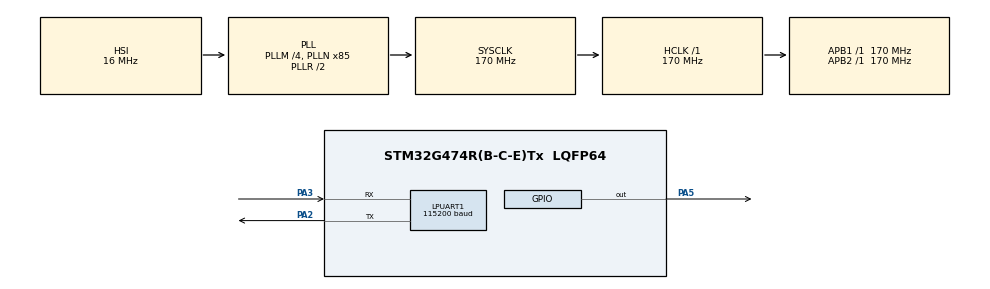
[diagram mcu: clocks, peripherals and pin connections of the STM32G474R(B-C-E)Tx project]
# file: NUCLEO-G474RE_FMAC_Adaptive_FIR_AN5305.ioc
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Dma.FMAC_PRELOAD.0.Direction=DMA_MEMORY_TO_MEMORY
Dma.FMAC_PRELOAD.0.EventEnable=DISABLE
Dma.FMAC_PRELOAD.0.Instance=DMA1_Channel1
Dma.FMAC_PRELOAD.0.MemDataAlignment=DMA_MDATAALIGN_WORD
Dma.FMAC_PRELOAD.0.MemInc=DMA_MINC_DISABLE
Dma.FMAC_PRELOAD.0.Mode=DMA_NORMAL
Dma.FMAC_PRELOAD.0.PeriphDataAlignment=DMA_PDATAALIGN_HALFWORD
Dma.FMAC_PRELOAD.0.PeriphInc=DMA_PINC_ENABLE
Dma.FMAC_PRELOAD.0.Polarity=HAL_DMAMUX_REQ_GEN_RISING
Dma.FMAC_PRELOAD.0.Priority=DMA_PRIORITY_HIGH
Dma.FMAC_PRELOAD.0.RequestNumber=1
Dma.FMAC_PRELOAD.0.SignalID=NONE
Dma.FMAC_PRELOAD.0.SyncEnable=DISABLE
Dma.FMAC_PRELOAD.0.SyncPolarity=HAL_DMAMUX_SYNC_NO_EVENT
Dma.FMAC_PRELOAD.0.SyncRequestNumber=1
Dma.FMAC_PRELOAD.0.SyncSignalID=NONE
Dma.FMAC_READ.2.Direction=DMA_PERIPH_TO_MEMORY
Dma.FMAC_READ.2.EventEnable=DISABLE
Dma.FMAC_READ.2.Instance=DMA1_Channel3
Dma.FMAC_READ.2.MemDataAlignment=DMA_MDATAALIGN_HALFWORD
Dma.FMAC_READ.2.MemInc=DMA_MINC_ENABLE
Dma.FMAC_READ.2.Mode=DMA_NORMAL
Dma.FMAC_READ.2.PeriphDataAlignment=DMA_PDATAALIGN_WORD
Dma.FMAC_READ.2.PeriphInc=DMA_PINC_DISABLE
Dma.FMAC_READ.2.Polarity=HAL_DMAMUX_REQ_GEN_RISING
Dma.FMAC_READ.2.Priority=DMA_PRIORITY_HIGH
Dma.FMAC_READ.2.RequestNumber=1
Dma.FMAC_READ.2.SignalID=NONE
Dma.FMAC_READ.2.SyncEnable=DISABLE
Dma.FMAC_READ.2.SyncPolarity=HAL_DMAMUX_SYNC_NO_EVENT
Dma.FMAC_READ.2.SyncRequestNumber=1
Dma.FMAC_READ.2.SyncSignalID=NONE
Dma.FMAC_WRITE.1.Direction=DMA_MEMORY_TO_PERIPH
Dma.FMAC_WRITE.1.EventEnable=DISABLE
Dma.FMAC_WRITE.1.Instance=DMA1_Channel2
Dma.FMAC_WRITE.1.MemDataAlignment=DMA_MDATAALIGN_HALFWORD
Dma.FMAC_WRITE.1.MemInc=DMA_MINC_ENABLE
Dma.FMAC_WRITE.1.Mode=DMA_NORMAL
Dma.FMAC_WRITE.1.PeriphDataAlignment=DMA_PDATAALIGN_WORD
Dma.FMAC_WRITE.1.PeriphInc=DMA_PINC_DISABLE
Dma.FMAC_WRITE.1.Polarity=HAL_DMAMUX_REQ_GEN_RISING
Dma.FMAC_WRITE.1.Priority=DMA_PRIORITY_HIGH
Dma.FMAC_WRITE.1.RequestNumber=1
Dma.FMAC_WRITE.1.SignalID=NONE
Dma.FMAC_WRITE.1.SyncEnable=DISABLE
Dma.FMAC_WRITE.1.SyncPolarity=HAL_DMAMUX_SYNC_NO_EVENT
Dma.FMAC_WRITE.1.SyncRequestNumber=1
Dma.FMAC_WRITE.1.SyncSignalID=NONE
Dma.Request0=FMAC_PRELOAD
Dma.Request1=FMAC_WRITE
Dma.Request2=FMAC_READ
LPUART1.BaudRate=115200
Mcu.Family=STM32G4
Mcu.Name=STM32G474R(B-C-E)Tx
Mcu.Package=LQFP64
NVIC.DMA1_Channel1_IRQn=true\:0\:0\:false\:false\:true\:false\:true
NVIC.DMA1_Channel2_IRQn=true\:0\:0\:false\:false\:true\:false\:true
NVIC.DMA1_Channel3_IRQn=true\:0\:0\:false\:false\:true\:false\:true
NVIC.FMAC_IRQn=true\:1\:0\:true\:false\:true\:true\:true
NVIC.PriorityGroup=NVIC_PRIORITYGROUP_4
PA2.Mode=Asynchronous
PA2.Signal=LPUART1_TX
PA3.Mode=Asynchronous
PA3.Signal=LPUART1_RX
PA5.Signal=GPIO_Output
ProjectManager.HeapSize=0x200
ProjectManager.StackSize=0x400
ProjectManager.TargetToolchain=STM32CubeIDE
RCC.ADC12Freq_Value=170000000
RCC.ADC345Freq_Value=170000000
RCC.AHBFreq_Value=170000000
RCC.APB1Freq_Value=170000000
RCC.APB1TimFreq_Value=170000000
RCC.APB2Freq_Value=170000000
RCC.APB2TimFreq_Value=170000000
RCC.CortexFreq_Value=170000000
RCC.EXTERNAL_CLOCK_VALUE=12288000
RCC.HCLKFreq_Value=170000000
RCC.HSE_VALUE=24000000
RCC.HSI48_VALUE=48000000
RCC.HSI_VALUE=16000000
RCC.LSE_VALUE=32768
RCC.PLLM=RCC_PLLM_DIV4
RCC.PLLN=85
RCC.SYSCLKFreq_VALUE=170000000
RCC.SYSCLKSource=RCC_SYSCLKSOURCE_PLLCLK
RCC.USBFreq_Value=170000000
RCC.VCOOutputFreq_Value=340000000
VP_FMAC_VS_FMAC.Mode=FMAC_Activate
VP_SYS_VS_DBSignals.Mode=DisableDeadBatterySignals
board=NUCLEO-G474RE

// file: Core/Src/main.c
/* USER CODE BEGIN Header */
/**
  ******************************************************************************
  * @file    FMAC/FMAC_Adaptive_FIR_AN5305/Src/main.c
  * @author  MCD Application Team
  * @brief   This sample code shows how to use FMAC HAL API (FMAC instance)
  *          to perform an adaptive FIR filter in DMA mode.
  ******************************************************************************
  * @attention
  *
  * <h2><center>&copy; Copyright (c) 2019 STMicroelectronics.
  * All rights reserved.</center></h2>
  *
  * This software component is licensed by ST under BSD 3-Clause license,
  * the "License"; You may not use this file except in compliance with the
  * License. You may obtain a copy of the License at:
  *                        opensource.org/licenses/BSD-3-Clause
  *
  ******************************************************************************
  */
/* USER CODE END Header */
#include "main.h"

/* USER CODE BEGIN Includes */
#include <stdio.h>
#include "2ToneNoise.h"
#include "3ToneNoise.h"
//#include "stm32g4xx_nucleo.h"
/* USER CODE END Includes */

FMAC_HandleTypeDef hfmac;
DMA_HandleTypeDef hdma_fmac_preload;
DMA_HandleTypeDef hdma_fmac_write;
DMA_HandleTypeDef hdma_fmac_read;

UART_HandleTypeDef hlpuart1;

/* USER CODE BEGIN PV */
/* FMAC configuration structure */
FMAC_FilterConfigTypeDef sFmacConfig;

/* Array of input values in Q1.15 format */
static int16_t aInputValues[2][ARRAY_SIZE];

static int16_t aFilterCoeffB[COEFF_VECTOR_B_SIZE];

/* Array of calculated filtered data in Q1.15 format (two parts) */
static int16_t aCalculatedFilteredData[ARRAY_SIZE];

/* Expected number of calculated samples for the used aCalculatedFilteredDataX */
uint16_t CurrentInputArraySize;

/* Expected number of calculated samples for the used aCalculatedFilteredDataX */
uint16_t ExpectedCalculatedFilteredDataSize;

/* Status of the calculation */
__IO uint32_t FilterPreloadCallbackCount   = 0;
__IO uint32_t HalfGetDataCallbackCount     = 0;
__IO uint32_t GetDataCallbackCount         = 0;
__IO uint32_t OutputDataReadyCallbackCount = 0;
__IO uint32_t ErrorCount                   = 0;
uint32_t OldValue;

/* Frame selelector */
uint8_t OldFrame = 0;
uint8_t Frame = 1;
/* Auxiliary counter */
uint32_t Index;

float value_f32;

/* USER CODE END PV */

void SystemClock_Config(void);
static void MX_GPIO_Init(void);
static void MX_DMA_Init(void);
static void MX_FMAC_Init(void);
static void MX_LPUART1_UART_Init(void);
/* USER CODE BEGIN PFP */

#define PUTCHAR_PROTOTYPE int __io_putchar(int ch)

/* USER CODE END PFP */

int main(void)
{
  /* USER CODE BEGIN 1 */
  /* STM32G4xx HAL library initialization:
       - Configure the Flash prefetch
       - Systick timer is configured by default as source of time base, but user
         can eventually implement his proper time base source (a general purpose
         timer for example or other time source), keeping in mind that Time base
         duration should be kept 1ms since PPP_TIMEOUT_VALUEs are defined and
         handled in milliseconds basis.
       - Set NVIC Group Priority to 4
       - Low Level Initialization
     */
  /* USER CODE END 1 */

  /* MCU Configuration--------------------------------------------------------*/

  /* Reset of all peripherals, Initializes the Flash interface and the Systick. */
  HAL_Init();

  /* Configure the system clock */
  SystemClock_Config();

  /* USER CODE BEGIN SysInit */
  /* Configure LED2 */

  /* USER CODE END SysInit */

  /* Initialize all configured peripherals */
  MX_GPIO_Init();
  MX_DMA_Init();
  MX_FMAC_Init();
  MX_LPUART1_UART_Init();
  /* USER CODE BEGIN 2 */
  /* Fill first frame with input signal and zero the other frame */
  /* Normally samples would come from ADC or other source, in this example the */
  /* same data is reloaded from Flash */

  printf("TwoToneNoise\n");
  for (Index=0; Index<ARRAY_SIZE; Index++)
  {
    aInputValues[0][Index] = TwoToneNoise[Index];
    aInputValues[1][Index] = 0;
    printf("%d %d\n",Index, TwoToneNoise[Index]);
  }

  /* generate filter coefficents (in this example they are simply read from flash */
  printf("TwoToneFilter\n");
  for (Index=0; Index<COEFF_VECTOR_B_SIZE; Index++)
  {
    aFilterCoeffB[Index] = TwoToneFilter[Index];
    printf("%d %d\n",Index, TwoToneFilter[Index]);
  }

  /*## Static FMAC configuration parameters #################################*/
  sFmacConfig.InputBaseAddress  = INPUT_BUFFER_BASE;
  sFmacConfig.InputBufferSize   = INPUT_BUFFER_SIZE;
  sFmacConfig.InputThreshold    = INPUT_THRESHOLD;
  sFmacConfig.CoeffBaseAddress  = COEFFICIENT_BUFFER_BASE;
  sFmacConfig.CoeffBufferSize   = COEFFICIENT_BUFFER_SIZE;
  sFmacConfig.OutputBaseAddress = OUTPUT_BUFFER_BASE;
  sFmacConfig.OutputBufferSize  = OUTPUT_BUFFER_SIZE;
  sFmacConfig.OutputThreshold   = OUTPUT_THRESHOLD;
  sFmacConfig.pCoeffA           = NULL;
  sFmacConfig.CoeffASize        = 0;
  sFmacConfig.CoeffBSize        = COEFF_VECTOR_B_SIZE;
  sFmacConfig.Filter            = FMAC_FUNC_CONVO_FIR;
  sFmacConfig.InputAccess       = FMAC_BUFFER_ACCESS_DMA;
  sFmacConfig.OutputAccess      = FMAC_BUFFER_ACCESS_DMA;
#if defined(CLIP_ENABLED)
  sFmacConfig.Clip              = FMAC_CLIP_ENABLED;
#else
  sFmacConfig.Clip              = FMAC_CLIP_DISABLED;
#endif
  sFmacConfig.P                 = COEFF_VECTOR_B_SIZE;
  sFmacConfig.Q                 = FILTER_PARAM_Q_NOT_USED;
  sFmacConfig.R                 = GAIN;

  /*### Main loop repeats each frame ########################################*/
  /* Repeat until required number of frames have been processed */
  do {
    /* Point to filter coefficients for current frame*/
    sFmacConfig.pCoeffB           = aFilterCoeffB;
    /* Configure filter and load coefficients by polling */
    if (HAL_FMAC_FilterConfig(&hfmac, &sFmacConfig) != HAL_OK)
    {
      /* Configuration Error */
      Error_Handler();
    }

    /* Preload the filter state at end of previous frame */
    if (HAL_FMAC_FilterPreload_DMA(&hfmac, &aInputValues[Frame][ARRAY_SIZE-COEFF_VECTOR_B_SIZE+1], COEFF_VECTOR_B_SIZE-1, NULL, 0) != HAL_OK)
    {
      /* Configuration Error */
      Error_Handler();
    }
    /* Switch input frames */
    OldFrame = Frame;
    Frame = (Frame ? 0 : 1);

    /* Wait for preload to finish */
    while (HAL_FMAC_GetState(&hfmac) != HAL_FMAC_STATE_READY);

    /* Start calculation of FIR filter in DMA mode */
    ExpectedCalculatedFilteredDataSize = ARRAY_SIZE;
    if (HAL_FMAC_FilterStart(&hfmac, aCalculatedFilteredData, &ExpectedCalculatedFilteredDataSize) != HAL_OK)
    {
      /* Processing Error */
      Error_Handler();
    }

    /*## Append data to start the DMA process after the preloaded data handling ##*/
    CurrentInputArraySize = ARRAY_SIZE;
    if (HAL_FMAC_AppendFilterData(&hfmac,
                                &aInputValues[Frame][0],
                                &CurrentInputArraySize) != HAL_OK)
    {
      ErrorCount++;
    }
    /* While processing is going on, fill next frame with input signal */
    /* Normally samples would come from ADC or other source, in this example the */
    /* data are loaded from Flash */
    printf("ThreeToneNoise\n");
    for (Index=0; Index<ARRAY_SIZE; Index++)
    {
      aInputValues[OldFrame][Index] = ThreeToneNoise[Index];
      printf("%d %d\n",Index, ThreeToneNoise[Index]);
    }
    /* Update filter coefficients for next frame */
    /* Normally this would be done by the adaptive algorithm, in this example the */
    /* coefficients are loaded from flash */
    printf("ThreeToneFilter\n");
    for (Index=0; Index<COEFF_VECTOR_B_SIZE; Index++)
    {
      aFilterCoeffB[Index] = ThreeToneFilter[Index];
      printf("%d %d\n",Index, ThreeToneFilter[Index]);
    }
    /* Wait for FMAC to finish processing frame */
    while (OutputDataReadyCallbackCount == OldValue);
    OldValue = OutputDataReadyCallbackCount;

    /* Stop the calculation of FIR filter in polling/DMA mode */
    if (HAL_FMAC_FilterStop(&hfmac) != HAL_OK)
    {
      /* Processing Error */
      Error_Handler();
    }
  /* end of loop */
  } while(OutputDataReadyCallbackCount < DATA_RDY_CALLBACK_COUNT);
  {
    if(ErrorCount != 0)
    {
      /* Processing Error */
      Error_Handler();
    }
  }

  /*## Check the final error status ############################################*/
  if(ErrorCount != 0)
  {
    /* Processing Error */
    Error_Handler();
  }

  /* Reached the end of processing : Turn LED2 on */
  HAL_GPIO_WritePin(GPIOA, GPIO_PIN_5, SET);

//#ifdef PRINT_OUTPUT
//  printf("Filtered output for frame %d\n",Frame);
//  for (Index=0; Index<ARRAY_SIZE; Index++)
//    printf("%d\n",aCalculatedFilteredData[Index]);
//#endif

  #ifdef PRINT_OUTPUT
    printf("Filtered output for frame %d\n",Frame);
    for (Index=0; Index<ARRAY_SIZE; Index++)
      printf("%d %d\n",Index, aCalculatedFilteredData[Index]);
  #endif

  /* USER CODE END 2 */

  /* Infinite loop */
  while (1)
  {

  }
}

void SystemClock_Config(void)
{
  RCC_OscInitTypeDef RCC_OscInitStruct = {0};
  RCC_ClkInitTypeDef RCC_ClkInitStruct = {0};
  RCC_PeriphCLKInitTypeDef PeriphClkInit = {0};

  /** Configure the main internal regulator output voltage
  */
  HAL_PWREx_ControlVoltageScaling(PWR_REGULATOR_VOLTAGE_SCALE1_BOOST);
  /** Initializes the RCC Oscillators according to the specified parameters
  * in the RCC_OscInitTypeDef structure.
  */
  RCC_OscInitStruct.OscillatorType = RCC_OSCILLATORTYPE_HSI;
  RCC_OscInitStruct.HSIState = RCC_HSI_ON;
  RCC_OscInitStruct.HSICalibrationValue = RCC_HSICALIBRATION_DEFAULT;
  RCC_OscInitStruct.PLL.PLLState = RCC_PLL_ON;
  RCC_OscInitStruct.PLL.PLLSource = RCC_PLLSOURCE_HSI;
  RCC_OscInitStruct.PLL.PLLM = RCC_PLLM_DIV4;
  RCC_OscInitStruct.PLL.PLLN = 85;
  RCC_OscInitStruct.PLL.PLLP = RCC_PLLP_DIV2;
  RCC_OscInitStruct.PLL.PLLQ = RCC_PLLQ_DIV2;
  RCC_OscInitStruct.PLL.PLLR = RCC_PLLR_DIV2;
  if (HAL_RCC_OscConfig(&RCC_OscInitStruct) != HAL_OK)
  {
    Error_Handler();
  }
  /** Initializes the CPU, AHB and APB buses clocks
  */
  RCC_ClkInitStruct.ClockType = RCC_CLOCKTYPE_HCLK|RCC_CLOCKTYPE_SYSCLK
                              |RCC_CLOCKTYPE_PCLK1|RCC_CLOCKTYPE_PCLK2;
  RCC_ClkInitStruct.SYSCLKSource = RCC_SYSCLKSOURCE_PLLCLK;
  RCC_ClkInitStruct.AHBCLKDivider = RCC_SYSCLK_DIV1;
  RCC_ClkInitStruct.APB1CLKDivider = RCC_HCLK_DIV1;
  RCC_ClkInitStruct.APB2CLKDivider = RCC_HCLK_DIV1;

  if (HAL_RCC_ClockConfig(&RCC_ClkInitStruct, FLASH_LATENCY_4) != HAL_OK)
  {
    Error_Handler();
  }
  /** Initializes the peripherals clocks
  */
  PeriphClkInit.PeriphClockSelection = RCC_PERIPHCLK_LPUART1;
  PeriphClkInit.Lpuart1ClockSelection = RCC_LPUART1CLKSOURCE_PCLK1;
  if (HAL_RCCEx_PeriphCLKConfig(&PeriphClkInit) != HAL_OK)
  {
    Error_Handler();
  }
}

static void MX_FMAC_Init(void)
{

  hfmac.Instance = FMAC;
  if (HAL_FMAC_Init(&hfmac) != HAL_OK)
  {
    Error_Handler();
  }

}

static void MX_LPUART1_UART_Init(void)
{

  hlpuart1.Instance = LPUART1;
  hlpuart1.Init.BaudRate = 115200;
  hlpuart1.Init.WordLength = UART_WORDLENGTH_8B;
  hlpuart1.Init.StopBits = UART_STOPBITS_1;
  hlpuart1.Init.Parity = UART_PARITY_NONE;
  hlpuart1.Init.Mode = UART_MODE_TX_RX;
  hlpuart1.Init.HwFlowCtl = UART_HWCONTROL_NONE;
  hlpuart1.Init.OneBitSampling = UART_ONE_BIT_SAMPLE_DISABLE;
  hlpuart1.Init.ClockPrescaler = UART_PRESCALER_DIV1;
  hlpuart1.AdvancedInit.AdvFeatureInit = UART_ADVFEATURE_NO_INIT;
  if (HAL_UART_Init(&hlpuart1) != HAL_OK)
  {
    Error_Handler();
  }
  if (HAL_UARTEx_SetTxFifoThreshold(&hlpuart1, UART_TXFIFO_THRESHOLD_1_8) != HAL_OK)
  {
    Error_Handler();
  }
  if (HAL_UARTEx_SetRxFifoThreshold(&hlpuart1, UART_RXFIFO_THRESHOLD_1_8) != HAL_OK)
  {
    Error_Handler();
  }
  if (HAL_UARTEx_DisableFifoMode(&hlpuart1) != HAL_OK)
  {
    Error_Handler();
  }

}

static void MX_DMA_Init(void)
{

  /* DMA controller clock enable */
  __HAL_RCC_DMAMUX1_CLK_ENABLE();
  __HAL_RCC_DMA1_CLK_ENABLE();

  /* DMA interrupt init */
  /* DMA1_Channel1_IRQn interrupt configuration */
  HAL_NVIC_SetPriority(DMA1_Channel1_IRQn, 0, 0);
  HAL_NVIC_EnableIRQ(DMA1_Channel1_IRQn);
  /* DMA1_Channel2_IRQn interrupt configuration */
  HAL_NVIC_SetPriority(DMA1_Channel2_IRQn, 0, 0);
  HAL_NVIC_EnableIRQ(DMA1_Channel2_IRQn);
  /* DMA1_Channel3_IRQn interrupt configuration */
  HAL_NVIC_SetPriority(DMA1_Channel3_IRQn, 0, 0);
  HAL_NVIC_EnableIRQ(DMA1_Channel3_IRQn);

}

static void MX_GPIO_Init(void)
{
  GPIO_InitTypeDef GPIO_InitStruct = {0};

  /* GPIO Ports Clock Enable */
  __HAL_RCC_GPIOA_CLK_ENABLE();
  __HAL_RCC_GPIOC_CLK_ENABLE();

  /*Configure GPIO pin Output Level */
  HAL_GPIO_WritePin(GPIOA, GPIO_PIN_5, GPIO_PIN_RESET);

  /*Configure GPIO pin Output Level */
  HAL_GPIO_WritePin(GPIOC, GPIO_PIN_11, GPIO_PIN_RESET);

  /*Configure GPIO pin : PA5 */
  GPIO_InitStruct.Pin = GPIO_PIN_5;
  GPIO_InitStruct.Mode = GPIO_MODE_OUTPUT_PP;
  GPIO_InitStruct.Pull = GPIO_NOPULL;
  GPIO_InitStruct.Speed = GPIO_SPEED_FREQ_LOW;
  HAL_GPIO_Init(GPIOA, &GPIO_InitStruct);

  /*Configure GPIO pin : PC11 */
  GPIO_InitStruct.Pin = GPIO_PIN_11;
  GPIO_InitStruct.Mode = GPIO_MODE_OUTPUT_PP;
  GPIO_InitStruct.Pull = GPIO_NOPULL;
  GPIO_InitStruct.Speed = GPIO_SPEED_FREQ_LOW;
  HAL_GPIO_Init(GPIOC, &GPIO_InitStruct);

}

/* USER CODE BEGIN 4 */

PUTCHAR_PROTOTYPE
{
  /* Place your implementation of fputc here */
  /* e.g. write a character to the LPUART1 and Loop until the end of transmission */
  HAL_UART_Transmit(&hlpuart1, (uint8_t *)&ch, 1, 0xFFFF);

  return ch;
}

/**
  * @brief FMAC filter preload callback
  * @par hfmac: FMAC HAL handle
  * @retval None
  */
void HAL_FMAC_FilterPreloadCallback(FMAC_HandleTypeDef *hfmac)
{
  FilterPreloadCallbackCount++;;
}

/**
  * @brief FMAC half get data callback
  * @par hfmac: FMAC HAL handle
  * @retval None
  */
void HAL_FMAC_HalfGetDataCallback(FMAC_HandleTypeDef *hfmac)
{
  HalfGetDataCallbackCount++;
}

/**
  * @brief FMAC get data callback
  * @par hfmac: FMAC HAL handle
  * @retval None
  */
void HAL_FMAC_GetDataCallback(FMAC_HandleTypeDef *hfmac)
{
  GetDataCallbackCount++;
}

/**
  * @brief FMAC output data ready callback
  * @par hfmac: FMAC HAL handle
  * @retval None
  */
void HAL_FMAC_OutputDataReadyCallback(FMAC_HandleTypeDef *hfmac)
{
  OutputDataReadyCallbackCount++;
}

/**
  * @brief FMAC error callback
  * @par hfmac: FMAC HAL handle
  * @retval None
  */
void HAL_FMAC_ErrorCallback(FMAC_HandleTypeDef *hfmac)
{
  ErrorCount++;
}
/* USER CODE END 4 */

void Error_Handler(void)
{
  /* USER CODE BEGIN Error_Handler_Debug */
  /* User can add his own implementation to report the HAL error return state */
  while(1)
  {
    /* LED2 is blinking */
    HAL_GPIO_TogglePin(GPIOA, GPIO_PIN_5);
    HAL_Delay(500);
  }
  /* USER CODE END Error_Handler_Debug */
}

/************************ (C) COPYRIGHT STMicroelectronics *****END OF FILE****/
